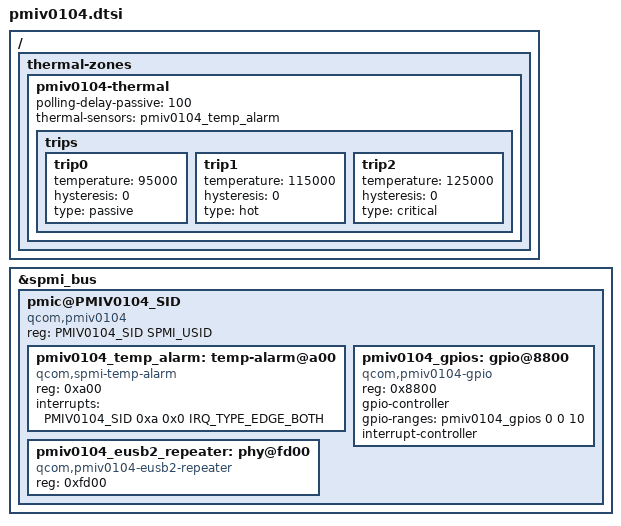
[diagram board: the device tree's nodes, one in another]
// SPDX-License-Identifier: BSD-3-Clause
/*
 * Copyright (c) 2025, Luca Weiss <luca.weiss@fairphone.com>
 */

#include <dt-bindings/interrupt-controller/irq.h>
#include <dt-bindings/spmi/spmi.h>

/ {
	thermal-zones {
		pmiv0104-thermal {
			polling-delay-passive = <100>;

			thermal-sensors = <&pmiv0104_temp_alarm>;

			trips {
				trip0 {
					temperature = <95000>;
					hysteresis = <0>;
					type = "passive";
				};

				trip1 {
					temperature = <115000>;
					hysteresis = <0>;
					type = "hot";
				};

				trip2 {
					/*
					 * Current Linux driver currently only supports up to
					 * 125°C, should be updated to 145°C once available.
					 */
					temperature = <125000>;
					hysteresis = <0>;
					type = "critical";
				};
			};
		};
	};
};

&spmi_bus {
	pmic@PMIV0104_SID {
		compatible = "qcom,pmiv0104", "qcom,spmi-pmic";
		reg = <PMIV0104_SID SPMI_USID>;
		#address-cells = <1>;
		#size-cells = <0>;

		pmiv0104_temp_alarm: temp-alarm@a00 {
			compatible = "qcom,spmi-temp-alarm";
			reg = <0xa00>;
			interrupts = <PMIV0104_SID 0xa 0x0 IRQ_TYPE_EDGE_BOTH>;
			#thermal-sensor-cells = <0>;
		};

		pmiv0104_gpios: gpio@8800 {
			compatible = "qcom,pmiv0104-gpio", "qcom,spmi-gpio";
			reg = <0x8800>;
			gpio-controller;
			gpio-ranges = <&pmiv0104_gpios 0 0 10>;
			#gpio-cells = <2>;
			interrupt-controller;
			#interrupt-cells = <2>;
		};

		pmiv0104_eusb2_repeater: phy@fd00 {
			compatible = "qcom,pmiv0104-eusb2-repeater";
			reg = <0xfd00>;
			#phy-cells = <0>;
		};
	};
};
